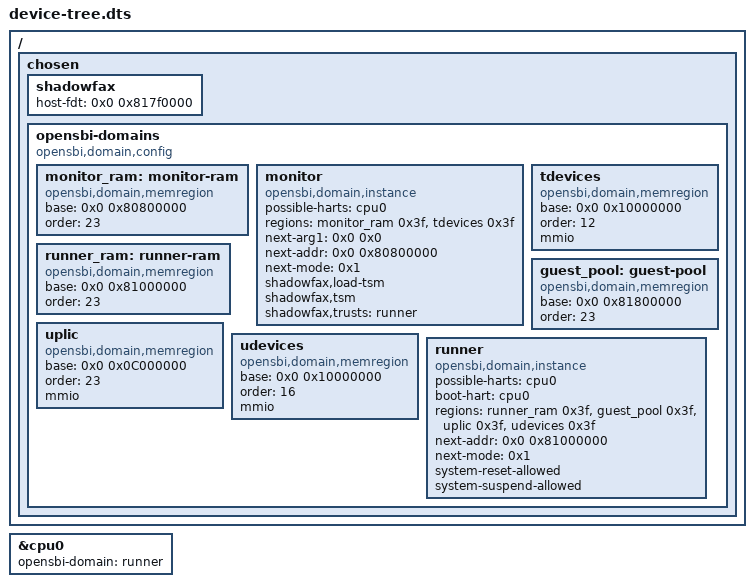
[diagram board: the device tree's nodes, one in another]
/dts-v1/;

/include/ "platform/generic/base.dtsi"

/ {
	chosen {
		shadowfax {
			host-fdt = <0x0 0x817f0000>;
		};

		opensbi-domains {
			compatible = "opensbi,domain,config";

			monitor_ram: monitor-ram {
				compatible = "opensbi,domain,memregion";
				base = <0x0 0x80800000>;
				order = <23>;
			};

			monitor: monitor {
				compatible = "opensbi,domain,instance";
				possible-harts = <&cpu0>;
				regions = <&monitor_ram 0x3f>, <&tdevices 0x3f>;
				next-arg1 = <0x0 0x0>;
				next-addr = <0x0 0x80800000>;
				next-mode = <0x1>;
				shadowfax,load-tsm;
				shadowfax,tsm;
				shadowfax,trusts = <&runner>;
			};

			tdevices: tdevices {
				compatible = "opensbi,domain,memregion";
				base = <0x0 0x10000000>;
				order = <12>;
				mmio;
			};

			runner_ram: runner-ram {
				compatible = "opensbi,domain,memregion";
				base = <0x0 0x81000000>;
				order = <23>;
			};

			guest_pool: guest-pool {
				compatible = "opensbi,domain,memregion";
				base = <0x0 0x81800000>;
				order = <23>;
			};

			uplic: uplic {
				compatible = "opensbi,domain,memregion";
				base = <0x0 0x0C000000>;
				order = <23>;
				mmio;
			};

			udevices: udevices {
				compatible = "opensbi,domain,memregion";
				base = <0x0 0x10000000>;
				order = <16>;
				mmio;
			};

			runner: runner {
				compatible = "opensbi,domain,instance";
				possible-harts = <&cpu0>;
				boot-hart = <&cpu0>;
				regions = <&runner_ram 0x3f>, <&guest_pool 0x3f>, <&uplic 0x3f>, <&udevices 0x3f>;
				next-addr = <0x0 0x81000000>;
				next-mode = <0x1>;
				system-reset-allowed;
				system-suspend-allowed;
			};

		};
	};
};

/* OpenSBI assigns a hart to a domain from the CPU node's opensbi-domain
   phandle; possible-harts only declares eligibility. Without this the hart
   stays in the root domain and the TSM's trust map never matches the caller. */
&cpu0 {
	opensbi-domain = <&runner>;
};
